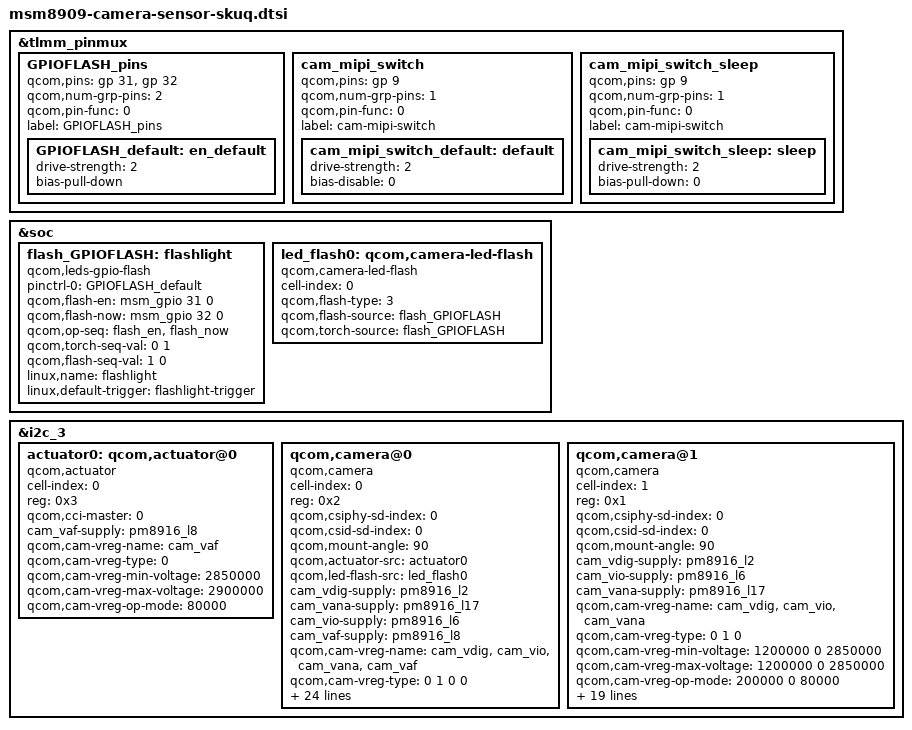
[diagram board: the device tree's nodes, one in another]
/*
 * Copyright (c) 2016, The Linux Foundation. All rights reserved.
 *
 * This program is free software; you can redistribute it and/or modify
 * it under the terms of the GNU General Public License version 2 and
 * only version 2 as published by the Free Software Foundation.
 *
 * This program is distributed in the hope that it will be useful,
 * but WITHOUT ANY WARRANTY; without even the implied warranty of
 * MERCHANTABILITY or FITNESS FOR A PARTICULAR PURPOSE.  See the
 * GNU General Public License for more details.
 */
&tlmm_pinmux {
	GPIOFLASH_pins {
		qcom,pins = <&gp 31>, <&gp 32>;
		qcom,num-grp-pins = <2>;
		qcom,pin-func = <0>;
		label = "GPIOFLASH_pins";
		GPIOFLASH_default: en_default {
		drive-strength = <2>;
		bias-pull-down;
		};
	};

	cam_mipi_switch {
		qcom,pins = <&gp 9>;
		qcom,num-grp-pins = <1>;
		qcom,pin-func = <0>;
		label = "cam-mipi-switch";
		/* active state */
		cam_mipi_switch_default: default {
			drive-strength = <2>; /* 2 MA */
			bias-disable = <0>; /* No PULL */
		};
	};

	cam_mipi_switch_sleep {
		qcom,pins = <&gp 9>;
		qcom,num-grp-pins = <1>;
		qcom,pin-func = <0>;
		label = "cam-mipi-switch";
		/* suspend state */
		cam_mipi_switch_sleep: sleep {
			drive-strength = <2>; /* 2 MA */
			bias-pull-down = <0>; /* PULL DOWN */
		};
	};
};

&soc {
	flash_GPIOFLASH:flashlight {
		compatible = "qcom,leds-gpio-flash";
		status = "okay";
		pinctrl-names = "flash_default";
		pinctrl-0 = <&GPIOFLASH_default>;
		qcom,flash-en = <&msm_gpio 31 0>;
		qcom,flash-now = <&msm_gpio 32 0>;
		qcom,op-seq = "flash_en", "flash_now";
		qcom,torch-seq-val = <0 1>;
		qcom,flash-seq-val = <1 0>;
		linux,name = "flashlight";
		linux,default-trigger = "flashlight-trigger";
	};
	led_flash0: qcom,camera-led-flash {
		cell-index = <0>;
		compatible = "qcom,camera-led-flash";
		qcom,flash-type = <3>;
		qcom,flash-source = <&flash_GPIOFLASH>;
		qcom,torch-source = <&flash_GPIOFLASH>;
	};
};

&i2c_3 {

	actuator0: qcom,actuator@0 {
		cell-index = <0>;
		reg = <0x3>;
		compatible = "qcom,actuator";
		qcom,cci-master = <0>;
		cam_vaf-supply = <&pm8916_l8>;
		qcom,cam-vreg-name = "cam_vaf";
		qcom,cam-vreg-type = <0>;
		qcom,cam-vreg-min-voltage = <2850000>;
		qcom,cam-vreg-max-voltage = <2900000>;
		qcom,cam-vreg-op-mode = <80000>;
	};

	qcom,camera@0 {
		cell-index = <0>;
		compatible = "qcom,camera";
		reg = <0x2>;
		qcom,csiphy-sd-index = <0>;
		qcom,csid-sd-index = <0>;
		qcom,mount-angle = <90>;
		qcom,actuator-src = <&actuator0>;
		qcom,led-flash-src = <&led_flash0>;
		cam_vdig-supply = <&pm8916_l2>;
		cam_vana-supply = <&pm8916_l17>;
		cam_vio-supply = <&pm8916_l6>;
		cam_vaf-supply = <&pm8916_l8>;
		qcom,cam-vreg-name = "cam_vdig", "cam_vio", "cam_vana",
			"cam_vaf";
		qcom,cam-vreg-type = <0 1 0 0>;
		qcom,cam-vreg-min-voltage = <1200000 0 2800000 2850000>;
		qcom,cam-vreg-max-voltage = <1200000 0 2850000 2900000>;
		qcom,cam-vreg-op-mode = <200000 0 80000 100000>;
		pinctrl-names = "cam_default", "cam_suspend";
		pinctrl-0 = <&cam_sensor_mclk0_default
			&cam_sensor_rear_default &cam_mipi_switch_default>;
		pinctrl-1 = <&cam_sensor_mclk0_sleep &cam_sensor_rear_sleep
			&cam_mipi_switch_sleep>;
		gpios = <&msm_gpio 26 0>,
			<&msm_gpio 35 0>,
			<&msm_gpio 34 0>,
			<&msm_gpio 9 0>;
		qcom,gpio-reset = <1>;
		qcom,gpio-standby = <2>;
		qcom,gpio-custom1 = <3>;
		qcom,gpio-req-tbl-num = <0 1 2 3>;
		qcom,gpio-req-tbl-flags = <1 0 0 0>;
		qcom,gpio-req-tbl-label = "CAMIF_MCLK",
			"CAM_RESET1",
			"CAM_STANDBY",
			"CAM_MIPI_SWITCH";
		qcom,sensor-position = <0>;
		qcom,sensor-mode = <0>;
		qcom,cci-master = <0>;
		status = "ok";
		clocks = <&clock_gcc clk_mclk0_clk_src>,
			<&clock_gcc clk_gcc_camss_mclk0_clk>;
		clock-names = "cam_src_clk", "cam_clk";
	};

	qcom,camera@1 {
		cell-index = <1>;
		compatible = "qcom,camera";
		reg = <0x1>;
		qcom,csiphy-sd-index = <0>;
		qcom,csid-sd-index = <0>;
		qcom,mount-angle = <90>;
		cam_vdig-supply = <&pm8916_l2>;
		cam_vio-supply = <&pm8916_l6>;
		cam_vana-supply = <&pm8916_l17>;
		qcom,cam-vreg-name = "cam_vdig", "cam_vio", "cam_vana";
		qcom,cam-vreg-type = <0 1 0>;
		qcom,cam-vreg-min-voltage = <1200000 0 2850000>;
		qcom,cam-vreg-max-voltage = <1200000 0 2850000>;
		qcom,cam-vreg-op-mode = <200000 0 80000>;
		pinctrl-names = "cam_default", "cam_suspend";
		pinctrl-0 = <&cam_sensor_mclk1_default &cam_sensor_front_default
			&cam_mipi_switch_default>;
		pinctrl-1 = <&cam_sensor_mclk1_sleep &cam_sensor_front_sleep
			&cam_mipi_switch_sleep>;
		gpios = <&msm_gpio 27 0>,
			<&msm_gpio 28 0>,
			<&msm_gpio 33 0>,
			<&msm_gpio 9 0>;
		qcom,gpio-reset = <1>;
		qcom,gpio-standby = <2>;
		qcom,gpio-custom1 = <3>;
		qcom,gpio-req-tbl-num = <0 1 2 3>;
		qcom,gpio-req-tbl-flags = <1 0 0 0>;
		qcom,gpio-req-tbl-label = "CAMIF_MCLK",
			"CAM_RESET",
			"CAM_STANDBY",
			"CAM_MIPI_SWITCH";
		qcom,sensor-position = <1>;
		qcom,cci-master = <0>;
		status = "ok";
		clocks = <&clock_gcc clk_mclk1_clk_src>,
				<&clock_gcc clk_gcc_camss_mclk1_clk>;
		clock-names = "cam_src_clk", "cam_clk";
	};
};
